# STM8S207K6 register map
Vendor: STMicroelectronics; Series: STM8S/STM8AF, medium density; File version: 1.0
CPU: other r1p0, big endian, no MPU, no FPU, 4 interrupt priority bits
Registers are 8-bit, read-write, reset 0x0 unless marked. A register's access mark holds for its fields unless they carry their own. Offsets are from the block's base; [hi:lo] are bit positions; {n}, {i} and the like mark numbered series.

## IWDG
Base 0x000050E0
0x00 KR — IWDG key register
  [7:0] KEY
0x01 PR — IWDG prescaler register
  [2:0] PR
0x02 RLR reset 0xFF — IWDG reload register
  [7:0] RL

## OPT
Base 0x00004800
0x00 OPT0 — Read-out protection (ROP)
0x01 OPT1 — User boot code (UBC)
0x02 NOPT1 reset 0xFF — User boot code (UBC) (complementary byte)
0x03 OPT2 — Alternate function remapping (AFR)
0x04 NOPT2 reset 0xFF — Alternate function remapping (AFR) (complementary byte)
0x05 OPT3 — Watchdog option
0x06 NOPT3 reset 0xFF — Watchdog option (complementary byte)
0x07 OPT4 — Clock option
0x08 NOPT4 reset 0xFF — Clock option (complementary byte)
0x09 OPT5 — HSE clock startup
0x0A NOPT5 reset 0xFF — HSE clock startup (complementary byte)
0x0D OPT7 — Flash wait states
0x0E NOPT7 reset 0xFF — Flash wait states (complementary byte)
0x7E OPTBL — Bootloader
0x7F NOPTBL reset 0xFF — Bootloader (complementary byte)

## PORTA
Base 0x00005000
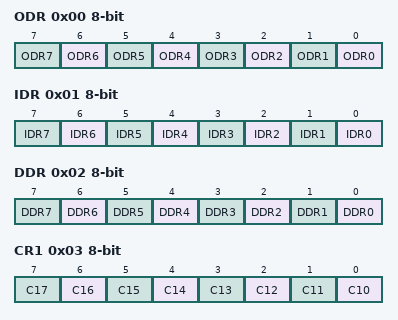
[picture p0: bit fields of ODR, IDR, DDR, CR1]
0x00 ODR — Port A data output latch register
  [n] ODR{n} (n=0..7)
0x01 IDR — Port A input pin value register
  [n] IDR{n} (n=0..7)
0x02 DDR — Port A data direction register
  [n] DDR{n} (n=0..7)
0x03 CR1 — Port A control register 1
  [n-10] C{n} (n=10..17)
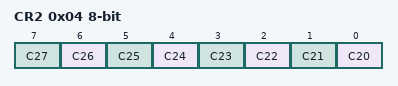
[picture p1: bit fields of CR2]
0x04 CR2 — Port A control register 2
  [n-20] C{n} (n=20..27)

## PORTB
Base 0x00005005
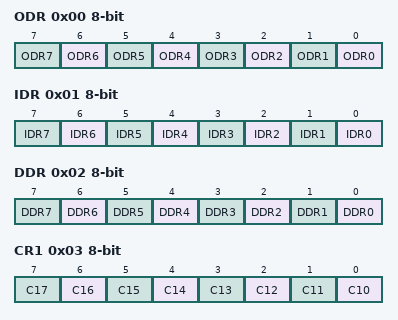
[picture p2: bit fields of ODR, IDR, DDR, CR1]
0x00 ODR — Port B data output latch register
  [n] ODR{n} (n=0..7)
0x01 IDR — Port B input pin value register
  [n] IDR{n} (n=0..7)
0x02 DDR — Port B data direction register
  [n] DDR{n} (n=0..7)
0x03 CR1 — Port B control register 1
  [n-10] C{n} (n=10..17)
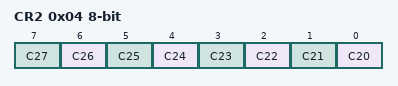
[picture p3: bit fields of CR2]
0x04 CR2 — Port B control register 2
  [n-20] C{n} (n=20..27)

## PORTC
Base 0x0000500A
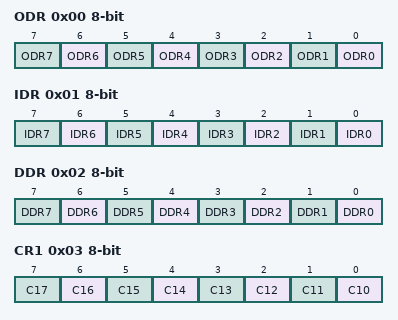
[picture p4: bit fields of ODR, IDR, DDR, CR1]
0x00 ODR — Port C data output latch register
  [n] ODR{n} (n=0..7)
0x01 IDR — Port C input pin value register
  [n] IDR{n} (n=0..7)
0x02 DDR — Port C data direction register
  [n] DDR{n} (n=0..7)
0x03 CR1 — Port C control register 1
  [n-10] C{n} (n=10..17)
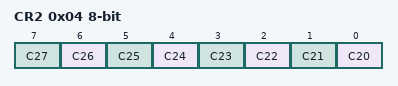
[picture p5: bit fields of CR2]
0x04 CR2 — Port C control register 2
  [n-20] C{n} (n=20..27)

## PORTD
Base 0x0000500F
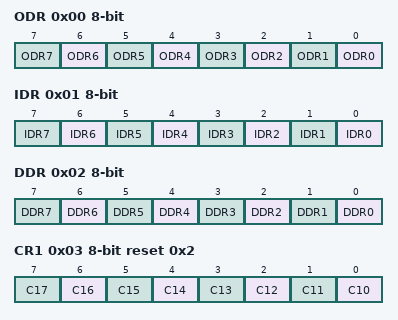
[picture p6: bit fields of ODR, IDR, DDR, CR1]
0x00 ODR — Port D data output latch register
  [n] ODR{n} (n=0..7)
0x01 IDR — Port D input pin value register
  [n] IDR{n} (n=0..7)
0x02 DDR — Port D data direction register
  [n] DDR{n} (n=0..7)
0x03 CR1 reset 0x2 — Port D control register 1
  [n-10] C{n} (n=10..17)
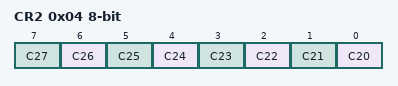
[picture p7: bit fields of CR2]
0x04 CR2 — Port D control register 2
  [n-20] C{n} (n=20..27)

## PORTE
Base 0x00005014
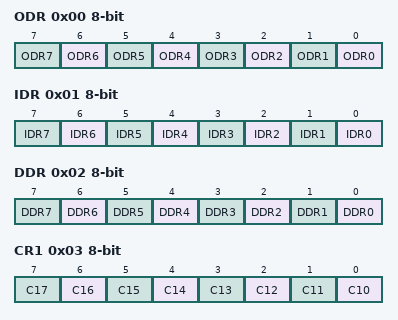
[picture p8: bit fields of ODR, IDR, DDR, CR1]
0x00 ODR — Port E data output latch register
  [n] ODR{n} (n=0..7)
0x01 IDR — Port E input pin value register
  [n] IDR{n} (n=0..7)
0x02 DDR — Port E data direction register
  [n] DDR{n} (n=0..7)
0x03 CR1 — Port E control register 1
  [n-10] C{n} (n=10..17)
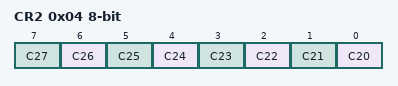
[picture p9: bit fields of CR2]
0x04 CR2 — Port E control register 2
  [n-20] C{n} (n=20..27)

## PORTF
Base 0x00005019
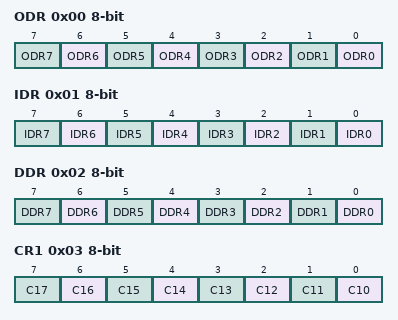
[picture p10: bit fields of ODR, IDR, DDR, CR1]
0x00 ODR — Port F data output latch register
  [n] ODR{n} (n=0..7)
0x01 IDR — Port F input pin value register
  [n] IDR{n} (n=0..7)
0x02 DDR — Port F data direction register
  [n] DDR{n} (n=0..7)
0x03 CR1 — Port F control register 1
  [n-10] C{n} (n=10..17)
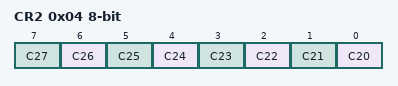
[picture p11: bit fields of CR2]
0x04 CR2 — Port F control register 2
  [n-20] C{n} (n=20..27)

## PORTG
Base 0x0000501E
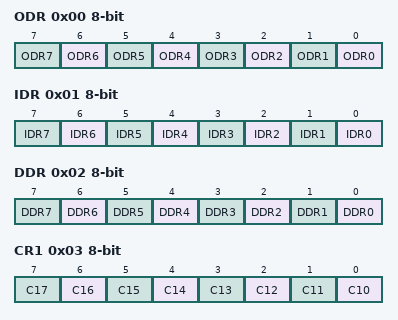
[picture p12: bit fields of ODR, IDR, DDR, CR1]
0x00 ODR — Port G data output latch register
  [n] ODR{n} (n=0..7)
0x01 IDR — Port G input pin value register
  [n] IDR{n} (n=0..7)
0x02 DDR — Port G data direction register
  [n] DDR{n} (n=0..7)
0x03 CR1 — Port G control register 1
  [n-10] C{n} (n=10..17)
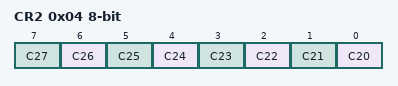
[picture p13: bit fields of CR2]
0x04 CR2 — Port G control register 2
  [n-20] C{n} (n=20..27)

## PORTH
Base 0x00005023
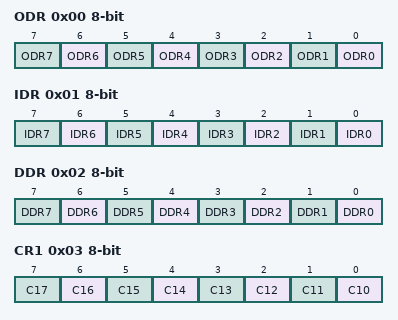
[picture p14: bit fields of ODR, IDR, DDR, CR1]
0x00 ODR — Port H data output latch register
  [n] ODR{n} (n=0..7)
0x01 IDR — Port H input pin value register
  [n] IDR{n} (n=0..7)
0x02 DDR — Port H data direction register
  [n] DDR{n} (n=0..7)
0x03 CR1 — Port H control register 1
  [n-10] C{n} (n=10..17)
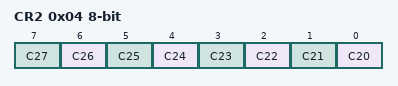
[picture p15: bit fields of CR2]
0x04 CR2 — Port H control register 2
  [n-20] C{n} (n=20..27)
